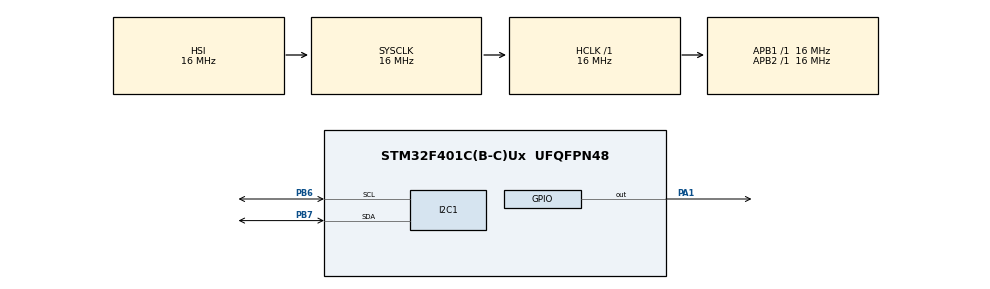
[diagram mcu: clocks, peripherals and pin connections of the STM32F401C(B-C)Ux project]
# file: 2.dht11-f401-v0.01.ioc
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Mcu.Family=STM32F4
Mcu.Name=STM32F401C(B-C)Ux
Mcu.Package=UFQFPN48
NVIC.PriorityGroup=NVIC_PRIORITYGROUP_4
PA1.Signal=GPIO_Output
PA13.Mode=Serial_Wire
PA13.Signal=SYS_JTMS-SWDIO
PA14.Mode=Serial_Wire
PA14.Signal=SYS_JTCK-SWCLK
PB6.Mode=I2C
PB6.Signal=I2C1_SCL
PB7.Mode=I2C
PB7.Signal=I2C1_SDA
PH0\ -\ OSC_IN.Mode=HSE-External-Oscillator
PH0\ -\ OSC_IN.Signal=RCC_OSC_IN
PH1\ -\ OSC_OUT.Mode=HSE-External-Oscillator
PH1\ -\ OSC_OUT.Signal=RCC_OSC_OUT
ProjectManager.HeapSize=0x200
ProjectManager.StackSize=0x400
ProjectManager.TargetToolchain=STM32CubeIDE
RCC.AHBFreq_Value=16000000
RCC.APB1Freq_Value=16000000
RCC.APB2Freq_Value=16000000
RCC.CortexFreq_Value=16000000
RCC.HSE_VALUE=25000000
RCC.HSI_VALUE=16000000
RCC.LSE_VALUE=32768
RCC.SYSCLKFreq_VALUE=16000000
RCC.VCOOutputFreq_Value=192000000
TIM2.ClockDivision=TIM_CLOCKDIVISION_DIV1
TIM2.Prescaler=15
TIM2.TIM_MasterOutputTrigger=TIM_TRGO_UPDATE
VP_TIM2_VS_ClockSourceINT.Mode=Internal
board=custom

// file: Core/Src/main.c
/* USER CODE BEGIN Header */
/**
  ******************************************************************************
  * @file           : main.c
  * @brief          : Main program body
  ******************************************************************************
  * @attention
  *
  * Copyright (c) 2026 STMicroelectronics.
  * All rights reserved.
  *
  * This software is licensed under terms that can be found in the LICENSE file
  * in the root directory of this software component.
  * If no LICENSE file comes with this software, it is provided AS-IS.
  *
  ******************************************************************************
  */
/* USER CODE END Header */
#include "main.h"
#include "i2c.h"
#include "tim.h"
#include "gpio.h"

/* USER CODE BEGIN Includes */
#include "dht11.h"
#include <stdio.h>
DHT11_Data_t dht11;
/* USER CODE END Includes */

/* USER CODE BEGIN PV */
int timer_test = 0;
int cnt = 0;
volatile uint8_t sensor_status = 0;
volatile uint8_t humidity_value = 0;
volatile uint8_t temperature_value = 0;

char uart_buffer[100];
/* USER CODE END PV */

void SystemClock_Config(void);

/* USER CODE BEGIN 0 */
static void DHT11_Delay_us(uint32_t us)
{
    uint32_t start = __HAL_TIM_GET_COUNTER(&htim2);

    while ((uint32_t)(__HAL_TIM_GET_COUNTER(&htim2) - start) < us);
}
/* USER CODE END 0 */

int main(void)
{

  /* MCU Configuration--------------------------------------------------------*/

  /* Reset of all peripherals, Initializes the Flash interface and the Systick. */
  HAL_Init();

  /* USER CODE BEGIN Init */
  HAL_TIM_Base_Start(&htim2);
  /* USER CODE END Init */

  /* Configure the system clock */
  SystemClock_Config();

  /* Initialize all configured peripherals */
  MX_GPIO_Init();
  MX_TIM2_Init();
  MX_I2C1_Init();

  /* Infinite loop */
  /* USER CODE BEGIN WHILE */
  while (1)
  {
	  timer_test = __HAL_TIM_GET_COUNTER(&htim2);
	  sensor_status = DHT11_ReadData(&dht11);

	          if (sensor_status == 1)
	          {
	              humidity_value = dht11.humidity;
	              temperature_value = dht11.temperature;

	          }

    /* USER CODE END WHILE */

    /* USER CODE BEGIN 3 */
	  cnt++;
	  HAL_Delay(100);
  }
  /* USER CODE END 3 */
}

void SystemClock_Config(void)
{
  RCC_OscInitTypeDef RCC_OscInitStruct = {0};
  RCC_ClkInitTypeDef RCC_ClkInitStruct = {0};

  /** Configure the main internal regulator output voltage
  */
  __HAL_RCC_PWR_CLK_ENABLE();
  __HAL_PWR_VOLTAGESCALING_CONFIG(PWR_REGULATOR_VOLTAGE_SCALE2);

  /** Initializes the RCC Oscillators according to the specified parameters
  * in the RCC_OscInitTypeDef structure.
  */
  RCC_OscInitStruct.OscillatorType = RCC_OSCILLATORTYPE_HSI;
  RCC_OscInitStruct.HSIState = RCC_HSI_ON;
  RCC_OscInitStruct.HSICalibrationValue = RCC_HSICALIBRATION_DEFAULT;
  RCC_OscInitStruct.PLL.PLLState = RCC_PLL_NONE;
  if (HAL_RCC_OscConfig(&RCC_OscInitStruct) != HAL_OK)
  {
    Error_Handler();
  }

  /** Initializes the CPU, AHB and APB buses clocks
  */
  RCC_ClkInitStruct.ClockType = RCC_CLOCKTYPE_HCLK|RCC_CLOCKTYPE_SYSCLK
                              |RCC_CLOCKTYPE_PCLK1|RCC_CLOCKTYPE_PCLK2;
  RCC_ClkInitStruct.SYSCLKSource = RCC_SYSCLKSOURCE_HSI;
  RCC_ClkInitStruct.AHBCLKDivider = RCC_SYSCLK_DIV1;
  RCC_ClkInitStruct.APB1CLKDivider = RCC_HCLK_DIV1;
  RCC_ClkInitStruct.APB2CLKDivider = RCC_HCLK_DIV1;

  if (HAL_RCC_ClockConfig(&RCC_ClkInitStruct, FLASH_LATENCY_0) != HAL_OK)
  {
    Error_Handler();
  }
}

void Error_Handler(void)
{
  __disable_irq();
  while (1)
  {
  }
}
